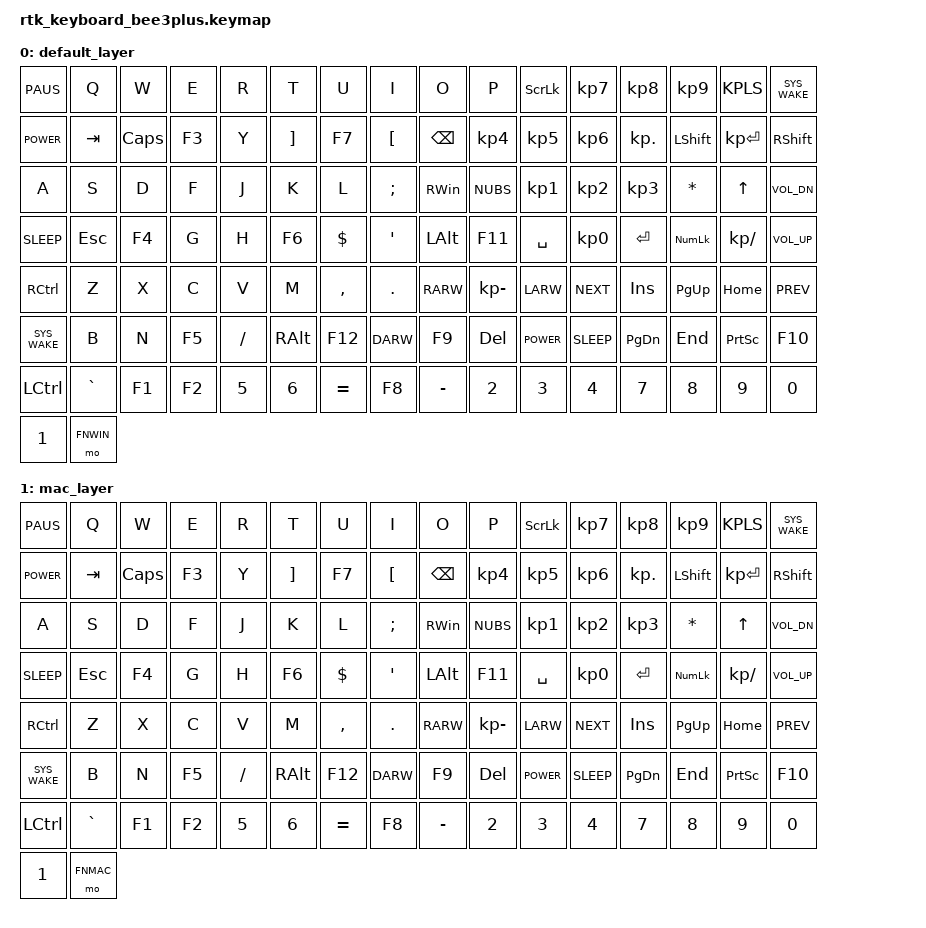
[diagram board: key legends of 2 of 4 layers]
/*
 * Copyright (c) 2023 The ZMK Contributors
 *
 * SPDX-License-Identifier: MIT
 */

#include <behaviors.dtsi>
#include <dt-bindings/zmk/bt.h>
#include <dt-bindings/zmk/keys.h>
#include <dt-bindings/zmk/rgb.h>

#define DEFAULT     0
#define MAC         1
#define FNWIN       2
#define FNMAC       3

/ {
    keymap {
        compatible = "zmk,keymap";

        default_layer {
            bindings = <
    &kp PAUS     &kp Q      &kp W     &kp E   &kp R      &kp T              &kp U       &kp I             &kp O         &kp P          &kp SCROLLLOCK   &kp KP_N7     &kp KP_N8     &kp KP_N9     &kp KPLS         &kp SYS_WAKE
    &kp C_POWER  &kp TAB    &kp CAPS  &kp F3  &kp Y      &kp RIGHT_BRACKET  &kp F7      &kp LEFT_BRACKET  &kp BACKSPACE &kp KP_N4      &kp KP_N5        &kp KP_N6     &kp KP_DOT    &kp LSHFT     &kp KP_ENTER     &kp RSHFT  
    &kp A        &kp S      &kp D     &kp F   &kp J      &kp K              &kp L       &kp SEMI          &kp RWIN      &kp NUBS       &kp KP_N1        &kp KP_N2     &kp KP_N3     &kp ASTERISK  &kp UP_ARROW     &kp K_VOL_DN
    &kp K_SLEEP  &kp ESC    &kp F4    &kp G   &kp H      &kp F6             &kp DOLLAR  &kp SQT           &kp LALT      &kp F11        &kp SPACE        &kp KP_N0     &kp ENTER     &kp KP_NLCK   &kp KP_SLASH     &kp K_VOL_UP   
    &kp RCTL     &kp Z      &kp X     &kp C   &kp V      &kp M              &kp COMMA   &kp DOT           &kp RARW      &kp KP_MINUS   &kp LARW         &kp C_NEXT    &kp INS       &kp PAGE_UP   &kp HOME         &kp C_PREV                            
    &kp SYS_WAKE &kp B      &kp N     &kp F5  &kp SLASH  &kp RALT           &kp F12     &kp DARW          &kp F9        &kp DEL        &kp K_POWER      &kp K_SLEEP   &kp PAGE_DOWN &kp END       &kp PRINTSCREEN  &kp F10
    &kp LCTL     &kp GRAVE  &kp F1    &kp F2  &kp N5     &kp N6             &kp EQUAL   &kp F8            &kp MINUS     &kp N2         &kp N3           &kp N4        &kp N7        &kp N8        &kp N9           &kp N0                           
    &kp N1       &mo FNWIN                  
            >;
        };
        mac_layer {
            bindings = <
    &kp PAUS     &kp Q      &kp W     &kp E   &kp R      &kp T              &kp U       &kp I             &kp O         &kp P          &kp SCROLLLOCK   &kp KP_N7     &kp KP_N8     &kp KP_N9     &kp KPLS         &kp SYS_WAKE
    &kp C_POWER  &kp TAB    &kp CAPS  &kp F3  &kp Y      &kp RIGHT_BRACKET  &kp F7      &kp LEFT_BRACKET  &kp BACKSPACE &kp KP_N4      &kp KP_N5        &kp KP_N6     &kp KP_DOT    &kp LSHFT     &kp KP_ENTER     &kp RSHFT  
    &kp A        &kp S      &kp D     &kp F   &kp J      &kp K              &kp L       &kp SEMI          &kp RWIN      &kp NUBS       &kp KP_N1        &kp KP_N2     &kp KP_N3     &kp ASTERISK  &kp UP_ARROW     &kp K_VOL_DN
    &kp K_SLEEP  &kp ESC    &kp F4    &kp G   &kp H      &kp F6             &kp DOLLAR  &kp SQT           &kp LALT      &kp F11        &kp SPACE        &kp KP_N0     &kp ENTER     &kp KP_NLCK   &kp KP_SLASH     &kp K_VOL_UP   
    &kp RCTL     &kp Z      &kp X     &kp C   &kp V      &kp M              &kp COMMA   &kp DOT           &kp RARW      &kp KP_MINUS   &kp LARW         &kp C_NEXT    &kp INS       &kp PAGE_UP   &kp HOME         &kp C_PREV                            
    &kp SYS_WAKE &kp B      &kp N     &kp F5  &kp SLASH  &kp RALT           &kp F12     &kp DARW          &kp F9        &kp DEL        &kp K_POWER      &kp K_SLEEP   &kp PAGE_DOWN &kp END       &kp PRINTSCREEN  &kp F10
    &kp LCTL     &kp GRAVE  &kp F1    &kp F2  &kp N5     &kp N6             &kp EQUAL   &kp F8            &kp MINUS     &kp N2         &kp N3           &kp N4        &kp N7        &kp N8        &kp N9           &kp N0                           
    &kp N1       &mo FNMAC 
            >;
        };

        fnwin_layer {
            bindings = <
    &none  &none    &none     &none          &none   &none   &none     &none      &none    &none            &none         &none         &none  &none  &none  &none
    &none  &none    &none     &kp LG(TAB)    &none   &none   &none     &kp C_PREV &none    &none            &none         &none         &none  &none  &none  &none
    &none  &none    &none     &none          &none   &none   &none     &none      &none    &none            &none         &none         &none  &none  &none  &none
    &none  &none    &none     &kp LG(E)      &none   &none   &kp LG(L) &none      &none    &none            &kp C_VOL_DN  &none         &none  &none  &none  &none
    &none  &none    &none     &none          &none   &none   &none     &none      &none    &none            &none         &none         &none  &none  &none  &none
    &none  &none    &none     &none          &none   &none   &none     &none      &none    &none            &none         &kp C_VOL_UP  &none  &none  &none  &none
    &none  &none    &kp C_BRI_DEC            &kp C_BRI_INC   &none     &none      &none    &kp C_PLAY_PAUSE &none         &kp C_NEXT    &none  &none  &none  &none
    &kp C_AC_SEARCH   &bt BT_SEL 0     &bt BT_SEL 1          &bt BT_SEL 2    &bt BT_CLR    &none            &none         &none         &none  &none  &kp C_MUTE  &none  &none  &none &none  &none
            >;
        };

        fnmac_layer {
            bindings = <
    &none  &none    &none     &none          &none   &none   &none   &none   &none      &none   &none         &none    &none       &none      &none     &none
    &none  &none    &none     &kp C_AC_DESKTOP_SHOW_ALL_WINDOWS      &none   &none      &none   &kp C_PREV    &none    &none       &none      &none     &none     &none  &none
    &none  &none    &none     &none          &none   &none   &none   &none   &none      &none   &none         &none    &none       &none      &none     &none
    &none  &none    &none     &kp C_AC_DESKTOP_SHOW_ALL_APPLICATIONS &none   &none      &kp LC(LG(Q))         &none    &none       &none      &kp C_VOL_DN        &none  &none  &none  &none   &none
    &none  &none    &none     &none          &none   &none   &none   &none   &none      &none   &none         &none    &none       &none      &none               &none
    &none  &none    &none     &none          &none   &none   &none   &none   &none      &none   &kp C_VOL_UP  &none    &none       &none      &none     &none
    &none  &none    &kp C_BRI_DEC            &kp C_BRI_INC   &none  &none    &none      &kp C_PLAY_PAUSE      &none    &none       &kp C_NEXT &none     &none     &none  &none  &none
    &kp C_AC_SEARCH   &bt BT_SEL 0  &bt BT_SEL 1   &bt BT_SEL 2   &bt BT_CLR &none      &none   &none         &none    &none       &kp C_MUTE &none     &none     &none  &none  &none
            >;
        };
    };
};

